VERSION ""

NS_ :

BS_:

BU_: ECU1 ECU2 Gateway

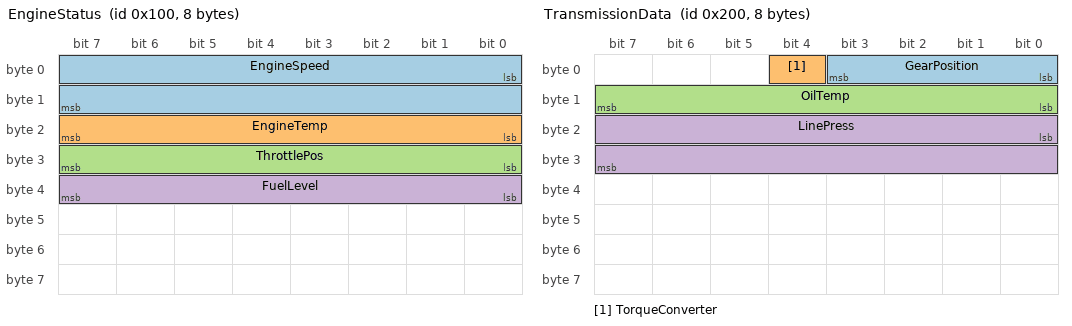
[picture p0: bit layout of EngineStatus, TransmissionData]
BO_ 256 EngineStatus: 8 ECU1
 SG_ EngineSpeed : 0|16@1+ (0.25,0) [0|16383.75] "rpm" ECU2
 SG_ EngineTemp : 16|8@1+ (1,-40) [-40|215] "degC" ECU2
 SG_ ThrottlePos : 24|8@1+ (0.392,0) [0|100] "percent" ECU2
 SG_ FuelLevel : 32|8@1+ (0.5,0) [0|127.5] "percent" ECU2

BO_ 512 TransmissionData: 8 ECU1
 SG_ GearPosition : 0|4@1+ (1,0) [0|15] "" ECU2
 SG_ TorqueConverter : 4|1@1+ (1,0) [0|1] "" ECU2
 SG_ OilTemp : 8|8@1+ (1,-40) [-40|215] "degC" ECU2
 SG_ LinePress : 16|16@1+ (0.1,0) [0|6553.5] "psi" ECU2

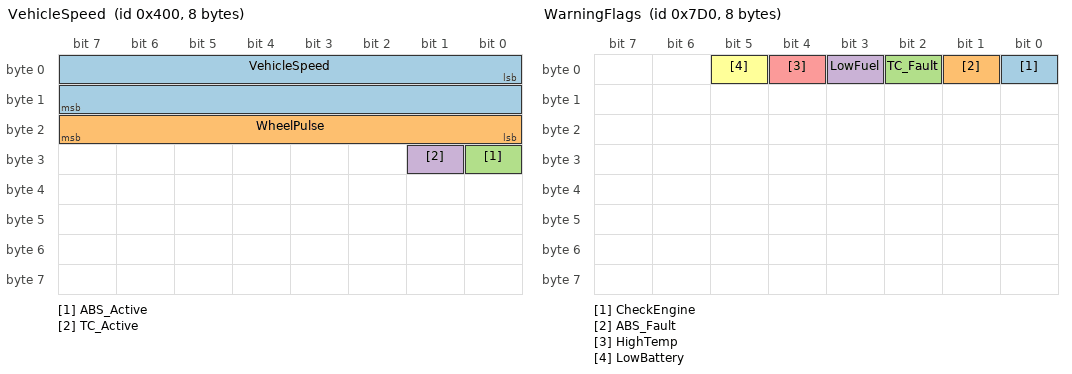
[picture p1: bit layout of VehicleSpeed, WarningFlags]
BO_ 1024 VehicleSpeed: 8 ECU1
 SG_ VehicleSpeed : 0|16@1+ (0.01,0) [0|655.35] "km/h" ECU2,Gateway
 SG_ WheelPulse : 16|8@1+ (1,0) [0|255] "count" ECU2
 SG_ ABS_Active : 24|1@1+ (1,0) [0|1] "" ECU2
 SG_ TC_Active : 25|1@1+ (1,0) [0|1] "" ECU2

BO_ 1536 BatteryStatus: 4 ECU1
 SG_ BatteryVoltage : 0|16@1+ (0.01,9) [9|16.38] "V" ECU2
 SG_ ChargingCurrent : 16|16@1- (0.1,-3276.8) [-3276.8|3276.8] "A" ECU2

BO_ 2000 WarningFlags: 8 Gateway
 SG_ CheckEngine : 0|1@1+ (1,0) [0|1] "" ECU1,ECU2
 SG_ ABS_Fault : 1|1@1+ (1,0) [0|1] "" ECU1,ECU2
 SG_ TC_Fault : 2|1@1+ (1,0) [0|1] "" ECU1,ECU2
 SG_ LowFuel : 3|1@1+ (1,0) [0|1] "" ECU1,ECU2
 SG_ HighTemp : 4|1@1+ (1,0) [0|1] "" ECU1,ECU2
 SG_ LowBattery : 5|1@1+ (1,0) [0|1] "" ECU1,ECU2

VAL_ 512 GearPosition 0 "Park" 1 "Reverse" 2 "Neutral" 3 "Drive" 15 "Invalid" ;

CM_ BO_ 256 "Engine parameters from ECU1";
CM_ BO_ 512 "Transmission status and oil temperature";
CM_ BO_ 1024 "Vehicle speed and wheel pulse data";
CM_ BO_ 1536 "Battery voltage and charging current";
CM_ BO_ 2000 "Various system warning flags";
CM_ SG_ 256 EngineSpeed "Engine RPM measured from crankshaft";
CM_ SG_ 256 EngineTemp "Coolant temperature";
CM_ SG_ 512 GearPosition "Current gear selection";
CM_ SG_ 1024 VehicleSpeed "Calculated vehicle speed from wheel pulses";
